# f28p551x_dev_cfg_regs register map
Vendor: Texas Instruments
Peripheral module from a debugger description file (folder C2000).
Address unit: 16 bits
Registers are 32-bit, read-write, no defined reset value unless marked. A register's access mark holds for its fields unless they carry their own. Offsets are as the file gives them; lines under a group give offsets from that group; [hi:lo] are bit positions; {n}, {i} and the like mark numbered series; 'fields as' and 'values as' point back to an identical list; <NAME> marks a mode.

## DEV_CFG_REGS — DEV CFG Registers
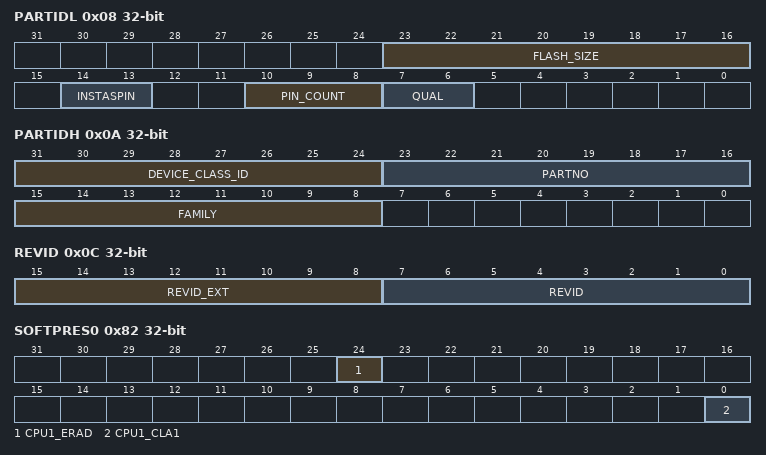
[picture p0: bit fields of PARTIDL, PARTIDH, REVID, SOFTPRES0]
0x08 PARTIDL — Lower 32-bit of Device PART Identification Number
  [23:16] FLASH_SIZE
  [14:13] INSTASPIN — Instaspin feature set
  [10:8] PIN_COUNT — Device Pin Count
  [7:6] QUAL — Qualification Status
0x0A PARTIDH access per field — Upper 32-bit of Device PART Identification Number
  [31:24] DEVICE_CLASS_ID ro
  [23:16] PARTNO rw — Device part number
  [15:8] FAMILY rw — Device family
0x0C REVID access per field — Device Revision Number
  [15:8] REVID_EXT ro — Device Revision ID Extension
  [7:0] REVID rw — Device Revision ID. This is specific to the Device
0x74 TRIMERRSTS — TRIM Error Status register
  [15:0] LERR — TRIM Load error status
0x82 SOFTPRES0 — Processing Block Software Reset register
  [24] CPU1_ERAD — ERAD Module reset bit
  [0] CPU1_CLA1 — CPU1_CLA1 software reset bit
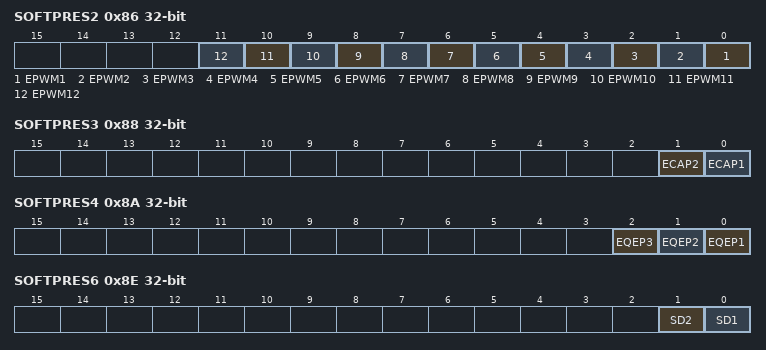
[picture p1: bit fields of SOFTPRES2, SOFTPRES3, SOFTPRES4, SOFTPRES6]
0x86 SOFTPRES2 — EPWM Software Reset register
  [n-1] EPWM{n} (n=1..12) — EPWM{n} software reset bit
0x88 SOFTPRES3 — ECAP Software Reset register
  [1] ECAP2 — ECAP2 software reset bit
  [0] ECAP1 — ECAP1 software reset bit
0x8A SOFTPRES4 — EQEP Software Reset register
  [2] EQEP3 — EQEP3 software reset bit
  [1] EQEP2 — EQEP2 software reset bit
  [0] EQEP1 — EQEP1 software reset bit
0x8E SOFTPRES6 — Sigma Delta Software Reset register
  [1] SD2 — SD2 software reset bit
  [0] SD1 — SD1 software reset bit
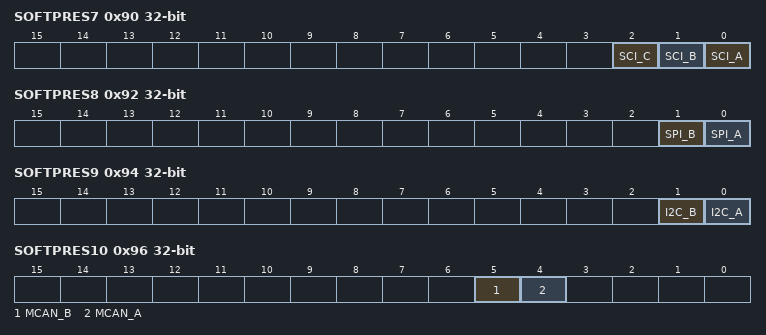
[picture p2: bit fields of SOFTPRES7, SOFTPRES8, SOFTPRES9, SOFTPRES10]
0x90 SOFTPRES7 — SCI Software Reset register
  [2] SCI_C — SCI_C software reset bit
  [1] SCI_B — SCI_B software reset bit
  [0] SCI_A — SCI_A software reset bit
0x92 SOFTPRES8 — SPI Software Reset register
  [1] SPI_B — SPI_B software reset bit
  [0] SPI_A — SPI_A software reset bit
0x94 SOFTPRES9 — I2C Software Reset register
  [1] I2C_B — I2C_B software reset bit
  [0] I2C_A — I2C_A software reset bit
0x96 SOFTPRES10 — CAN Software Reset register
  [5] MCAN_B — MCAN_B software reset bit
  [4] MCAN_A — MCAN_A software reset bit
0x98 SOFTPRES11 — McBSP/USB Software Reset register
  [16] USB_A — USB_A software reset bit
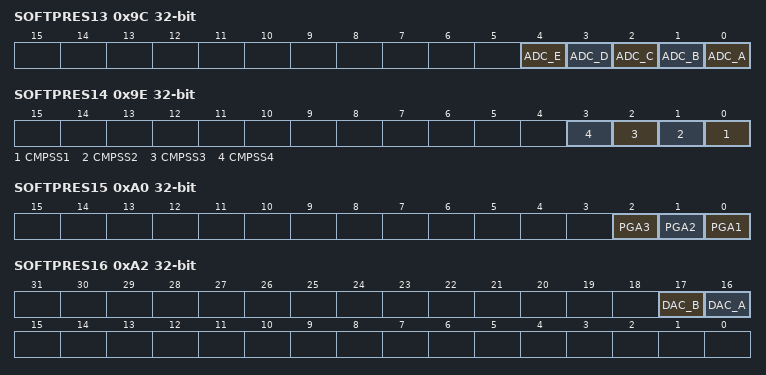
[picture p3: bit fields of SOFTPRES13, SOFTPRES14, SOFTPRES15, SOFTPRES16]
0x9C SOFTPRES13 — ADC Software Reset register
  [4] ADC_E — ADC_E software reset bit
  [3] ADC_D — ADC_D software reset bit
  [2] ADC_C — ADC_C software reset bit
  [1] ADC_B — ADC_B software reset bit
  [0] ADC_A — ADC_A software reset bit
0x9E SOFTPRES14 — CMPSS Software Reset register
  [n-1] CMPSS{n} (n=1..4) — CMPSS{n} software reset bit
0xA0 SOFTPRES15 — PGA Software Reset register
  [2] PGA3 — PGA3 software reset bit
  [1] PGA2 — PGA2 software reset bit
  [0] PGA1 — PGA1 software reset bit
0xA2 SOFTPRES16 — DAC Software Reset register
  [17] DAC_B — Buffered_DAC_B software reset bit
  [16] DAC_A — Buffered_DAC_A software reset bit
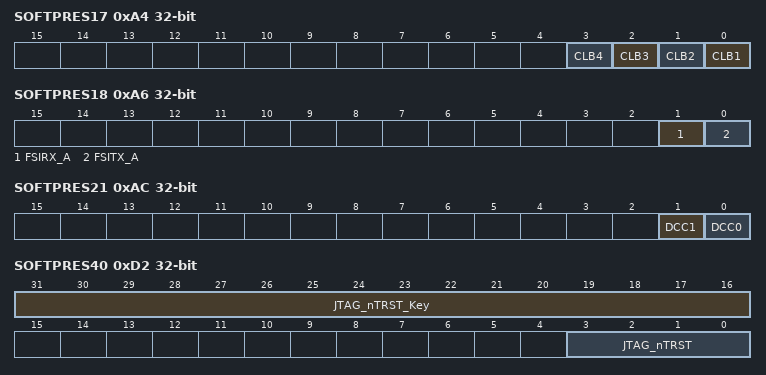
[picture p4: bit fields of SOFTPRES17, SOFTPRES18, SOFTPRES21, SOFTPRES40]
0xA4 SOFTPRES17 — CLB Software Reset register
  [n-1] CLB{n} (n=1..4) — CLB{n} software reset bit
0xA6 SOFTPRES18 — FSI Software Reset register
  [1] FSIRX_A — FSIRX_A software reset bit
  [0] FSITX_A — FSITX_A software reset bit
0xA8 SOFTPRES19 — LIN Software Reset register
  [0] LIN_A — LIN_A software reset bit
0xAA SOFTPRES20 — PMBUS Software Reset register
  [0] PMBUS_A — PMBUS_A software reset bit
0xAC SOFTPRES21 — DCC Software Reset register
  [1] DCC1 — DCC Module reset bit
  [0] DCC0 — DCC Module reset bit
0xB6 SOFTPRES26 — AES Software Reset register
  [0] AESA — AES Module Reset Bit
0xB8 SOFTPRES27 — EPG Software Reset register
  [0] EPG1 — EPG Module Reset Bit
0xBA SOFTPRES28 — Flash Software Reset register
  [0] FLASHA — Flash Wrapper Module Reset Bit
0xBE SOFTPRES30 — NPU Software reset register
  [0] NPU — NPU Module Reset Bit
0xD2 SOFTPRES40 — Peripheral Software Reset register
  [31:16] JTAG_nTRST_Key
  [3:0] JTAG_nTRST — Multi Bit JTAG nTRST
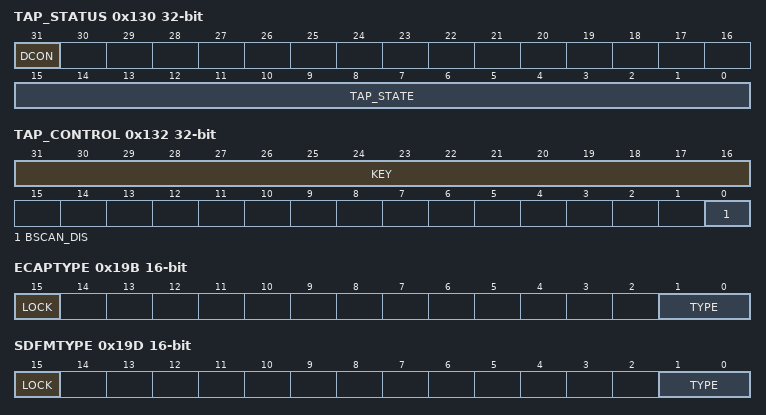
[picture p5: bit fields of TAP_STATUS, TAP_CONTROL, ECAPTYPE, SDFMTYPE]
0x130 TAP_STATUS ro — Status of JTAG State machine and Debugger Connect
  [31] DCON — Debugger Connect Indication
  [15:0] TAP_STATE — Present TAP State
0x132 TAP_CONTROL — Disable TAP control
  [31:16] KEY — Key value to enable write
  [0] BSCAN_DIS — Disable BSCAN TAP control
0x19B ECAPTYPE 16-bit — Configures ECAP Type for the device
  [15] LOCK — Lock bit for the register
  [1:0] TYPE — Configure ECAP type
0x19D SDFMTYPE 16-bit — Configures SDFM Type for the device
  [15] LOCK — Lock bit
  [1:0] TYPE — Configure SDFM type
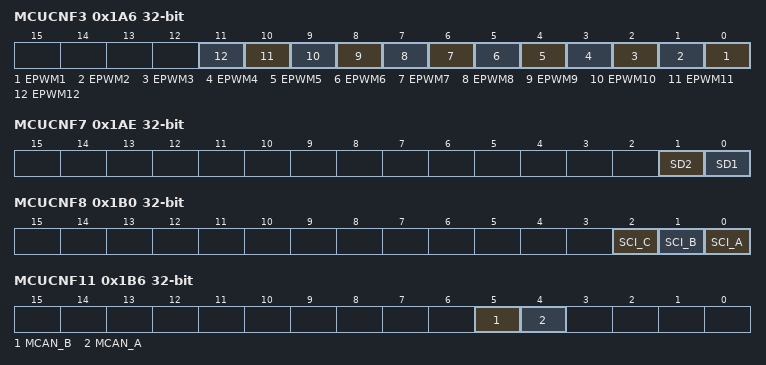
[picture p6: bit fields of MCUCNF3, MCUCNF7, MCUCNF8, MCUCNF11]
0x1A6 MCUCNF3 — MCU Configuration: ETPWM
  [n-1] EPWM{n} (n=1..12) — EPWM{n} Present
0x1AE MCUCNF7 — MCU Configuration: SDFM
  [1] SD2 — SD2 Present
  [0] SD1 — SD1 Present
0x1B0 MCUCNF8 — MCU Configuration: SCI
  [2] SCI_C — SCI_C Present
  [1] SCI_B — SCI_B Present
  [0] SCI_A — SCI_A Present
0x1B6 MCUCNF11 — MCU Configuration: CAN
  [5] MCAN_B — MCAN_B Present
  [4] MCAN_A — MCAN_A Present
0x1B8 MCUCNF12 — MCU Configuration: McBSP_USB
  [16] USB_A — Decides the capability of the USB_A Module
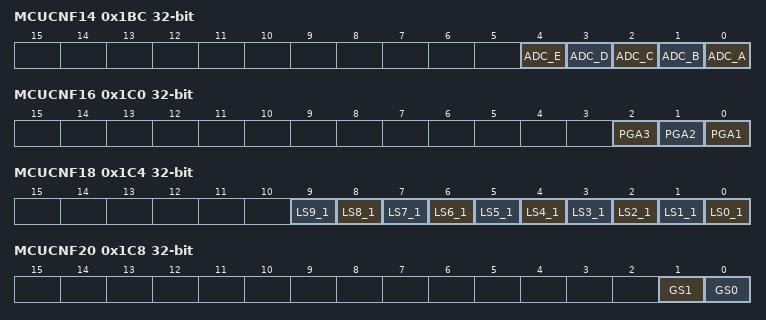
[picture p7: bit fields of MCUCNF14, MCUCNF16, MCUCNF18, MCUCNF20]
0x1BC MCUCNF14 — MCU Configuration: ADC
  [4] ADC_E — ADC_E Present
  [3] ADC_D — ADC_D Present
  [2] ADC_C — ADC_C Present
  [1] ADC_B — ADC_B Present
  [0] ADC_A — ADC_A Present
0x1C0 MCUCNF16 — MCU Configuration: PGA
  [2] PGA3 — PGA3 Present
  [1] PGA2 — PGA2 Present
  [0] PGA1 — PGA1 Present
0x1C4 MCUCNF18 — MCU Configuration: Lx.1 SRAM Customization
  [n] LS{n}_1 (n=0..9) — LS{n}_1 Present
0x1C8 MCUCNF20 — MCU Configuration: GSx SRAM Customization
  [1] GS1 — GS1 Present
  [0] GS0 — GS0 Present
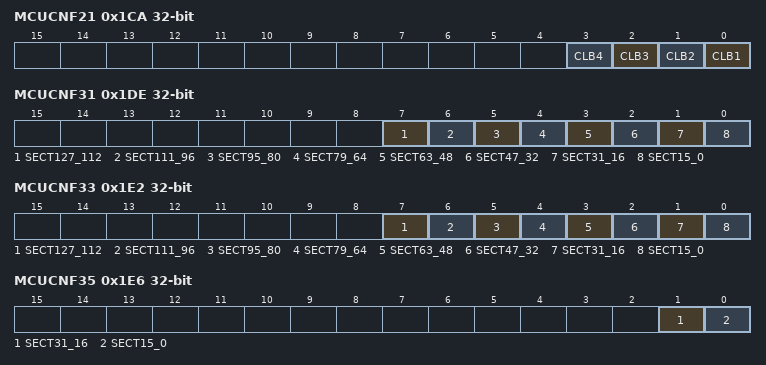
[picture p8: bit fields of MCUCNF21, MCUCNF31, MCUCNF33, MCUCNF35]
0x1CA MCUCNF21 — MCU Configuration: CLB
  [n-1] CLB{n} (n=1..4) — CLB{n} Present
0x1CE MCUCNF23 — MCU Configuration: LIN
  [0] LIN_A — LIN_A Present
0x1DE MCUCNF31 — MCU Configuration: Flash Bank0
  [7] SECT127_112 — Flash sectors 127_112 present
  [6] SECT111_96 — Flash sectors 111_96 present
  [5] SECT95_80 — Flash sectors 95_80 present
  [4] SECT79_64 — Flash sectors 79_64 present
  [3] SECT63_48 — Flash sectors 63_48 present
  [2] SECT47_32 — Flash sectors 47_32 present
  [1] SECT31_16 — Flash sectors 31_16 present
  [0] SECT15_0 — Flash sectors 15_0 present
0x1E2 MCUCNF33 — MCU Configuration: Flash Bank2
  fields as MCUCNF31
0x1E6 MCUCNF35 — MCU Configuration: Flash Bank4
  [1] SECT31_16 — Flash sectors 31_16 present
  [0] SECT15_0 — Flash sectors 15_0 present
0x1F8 MCUCNFLOCK — Lock bit for MCUCNFx registers
  [0] MCUCNFLOCK — Lock bit for MCUCNF registers
